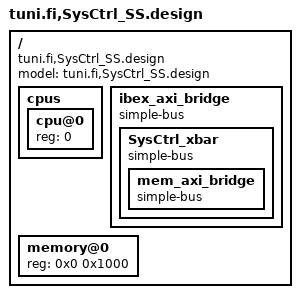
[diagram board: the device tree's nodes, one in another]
/dts-v1/;

/ {
	#address-cells = <1>;
	#size-cells = <1>;
	model = "tuni.fi,SysCtrl_SS.design";
	compatible = "tuni.fi,SysCtrl_SS.design";

	cpus {
		#address-cells = <1>;
		#size-cells = <0>;

		// 'ibex_core' in component tuni.fi:lowRISC:ibex:1.0
		cpu@0 {
			reg = <0>;
		};
	};

	// Instance 'core_dmem_bridge' of bridge component tuni.fi:lowRISC:ibex_axi_bridge:1.0
	ibex_axi_bridge {
		compatible = "simple-bus";
		#address-cells = <1>;
		#size-cells = <1>;

		// Instance 'Ctrl_xbar' of bridge component tuni.fi:ip:SysCtrl_xbar:1.0
		SysCtrl_xbar {
			compatible = "simple-bus";
			#address-cells = <1>;
			#size-cells = <1>;

			// Instance 'BootRom_axi_bridge' of bridge component tuni.fi:ip:mem_axi_bridge:1.0
			mem_axi_bridge {
				compatible = "simple-bus";
				#address-cells = <1>;
				#size-cells = <1>;

			};

			// Instance 'axi_dmem_bridge' of bridge component tuni.fi:ip:mem_axi_bridge:1.0
			mem_axi_bridge {
				compatible = "simple-bus";
				#address-cells = <1>;
				#size-cells = <1>;

			};

			// Instance 'axi_imem_bridge' of bridge component tuni.fi:ip:mem_axi_bridge:1.0
			mem_axi_bridge {
				compatible = "simple-bus";
				#address-cells = <1>;
				#size-cells = <1>;

			};

		};

	};

	// Memory map 'spRom' in instance 'BootRom' of component tuni.fi:ip:BootRom:1.0
	memory@0 {
		device_type = "memory";
		#address-cells = <1>;
		#size-cells = <1>;
		reg = <0x0 0x1000>;
	};

	// Memory map 'sram' in instance 'i_dmem' of component tuni.fi:memory.simulation:sp_sram:1.0
	memory@0 {
		device_type = "memory";
		#address-cells = <1>;
		#size-cells = <1>;
		reg = <0x0 0x1000>;
	};

	// Memory map 'sram' in instance 'i_imem' of component tuni.fi:memory.simulation:sp_sram:1.0
	memory@0 {
		device_type = "memory";
		#address-cells = <1>;
		#size-cells = <1>;
		reg = <0x0 0x1000>;
	};

};

